VERSION "DIPBNNNYYYYYYYYYYYNNNNNNNNNNNNYNNNNNNNNNNN/4/%%%/4/'%**4NNN///"

BS_:

BU_:

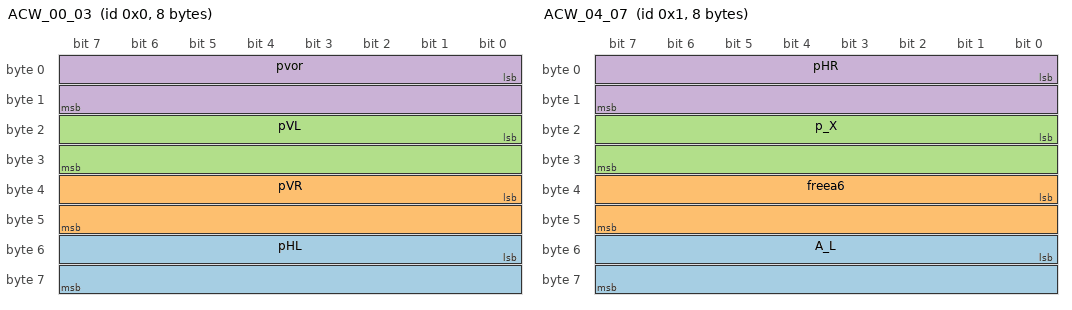
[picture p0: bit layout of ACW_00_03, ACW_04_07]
BO_ 0 ACW_00_03: 8 TX
 SG_ pHL : 48|16@1- (0.00813802,0) [0|250] "Bar" RX
 SG_ pVR : 32|16@1- (0.00813802,0) [0|250] "Bar" RX
 SG_ pVL : 16|16@1- (0.00813802,0) [0|250] "Bar" RX
 SG_ pvor : 0|16@1- (0.00813802,0) [0|250] "Bar" RX

BO_ 1 ACW_04_07: 8 TX
 SG_ A_L : 48|16@1- (0.000598756,0) [-15|15] "m/s²" RX
 SG_ freea6 : 32|16@1- (0.000305176,0) [0|250] "V" RX
 SG_ p_X : 16|16@1- (0.00813802,0) [0|250] "Bar" RX
 SG_ pHR : 0|16@1- (0.00813802,0) [0|250] "Bar" RX

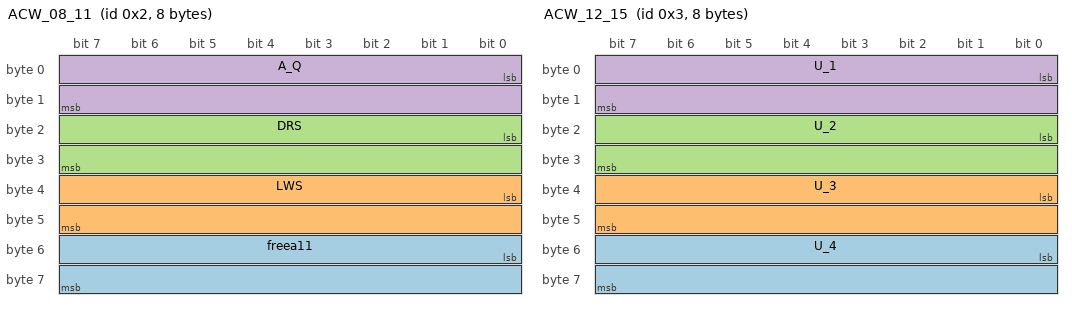
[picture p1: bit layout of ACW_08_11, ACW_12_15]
BO_ 2 ACW_08_11: 8 TX
 SG_ freea11 : 48|16@1- (0.000305176,0) [0|20] "V" RX
 SG_ LWS : 32|16@1- (0.000305176,0) [-180|180] "Grad" RX
 SG_ DRS : 16|16@1- (0.00338983,0) [-100|100] "°/s" RX
 SG_ A_Q : 0|16@1- (0.000598756,0) [-15|15] "m/s²" RX

BO_ 3 ACW_12_15: 8 TX
 SG_ U_4 : 48|16@1- (0.000305176,0) [0|20] "V" RX
 SG_ U_3 : 32|16@1- (0.000305176,0) [0|20] "V" RX
 SG_ U_2 : 16|16@1- (0.000305176,0) [0|20] "V" RX
 SG_ U_1 : 0|16@1- (0.000305176,0) [0|20] "V" RX

CM_ "  
!!!! do not edit - only for WinACW !!!!
[WINACWID] 1682 
[WINACWSIGNAL_T0] T_VL -50 950 °C 
[WINACWSIGNAL_T1] T_VR -50 950 °C 
[WINACWSIGNAL_T2] T_HL -50 950 °C 
[WINACWSIGNAL_T3] T_HR -50 950 °C 
[WINACWID] 1686 
[WINACWSIGNAL_T4] T_1_0 -50 950 °C 
[WINACWSIGNAL_T5] T_1_1 -50 950 °C 
[WINACWSIGNAL_T6] T_1_2 -50 950 °C 
[WINACWSIGNAL_T7] T_1_3 -50 950 °C 
[WINACWID] 1690 
[WINACWSIGNAL_T8] T_2_0 -50 950 °C 
[WINACWSIGNAL_T9] T_2_1 -50 950 °C 
[WINACWSIGNAL_T10] T_2_2 -50 950 °C 
[WINACWSIGNAL_T11] T_2_3 -50 950 °C 
[WINACWID] 1694 
[WINACWSIGNAL_T12] T_3_0 -50 950 °C 
[WINACWSIGNAL_T13] T_3_1 -50 950 °C 
[WINACWSIGNAL_T14] T_3_2 -50 950 °C 
[WINACWSIGNAL_T15] T_3_3 -50 950 °C 
[WINACWSIGNAL_S0] I0 0.0001530000 0.0000000000 -5 5 A 
[WINACWSIGNAL_S1] I1 0.0001530000 0.0000000000 -5 5 A 
[WINACWSIGNAL_S2] I2 0.0001530000 0.0000000000 -5 5 A 
[WINACWSIGNAL_S3] I3 0.0001530000 0.0000000000 -5 5 A 
[WINACWSIGNAL_S4] I4 0.0001530000 0.0000000000 -5 5 A 
[WINACWSIGNAL_S5] I5 0.0001530000 0.0000000000 -5 5 A 
[WINACWSIGNAL_S6] U0 0.0006100000 0.0000000000 -20 20 V 
[WINACWSIGNAL_S7] U1 0.0006100000 0.0000000000 -20 20 V 
[WINACWSIGNAL_S8] U2 0.0006100000 0.0000000000 -20 20 V 
[WINACWSIGNAL_S9] U3 0.0006100000 0.0000000000 -20 20 V 
[WINACWSIGNAL_S10] U4 0.0006100000 0.0000000000 -20 20 V 
[WINACWSIGNAL_S11] U5 0.0006100000 0.0000000000 -20 20 V 
[WINACWSIGNAL_D0] EVVL 
[WINACWSIGNAL_D1] AVVL 
[WINACWSIGNAL_D2] EVVR 
[WINACWSIGNAL_D3] AVVR 
[WINACWSIGNAL_D4] EVHL 
[WINACWSIGNAL_D5] AVHL 
[WINACWSIGNAL_D6] EVHR 
[WINACWSIGNAL_D7] AVHR 
[WINACWSIGNAL_D8] USV1 
[WINACWSIGNAL_D9] USV2 
[WINACWSIGNAL_D10] ASV1 
[WINACWSIGNAL_D11] ASV2 
[WINACWSIGNAL_D12] BA_LO 
[WINACWSIGNAL_D13] MRA 
[WINACWSIGNAL_D14] VLPR1 
[WINACWSIGNAL_D15] VLPR2 
[WINACWSIGNAL_D18] DATA 
[WINACWSIGNAL_D19] BA_HI 
[WINACWSIGNAL_D20] MT_SY 
[WINACWSIGNAL_D21] CLOCK 
[WINACWSIGNAL_R0] A_X 0.0200000000 -40.9600000000 -15 15 m/s² 
[WINACWSIGNAL_R1] A_Y 0.0200000000 -40.9600000000 -15 15 m/s² 
[WINACWSIGNAL_R2] YawRate_Z 0.0800000000 -163.8400000000 -100 100 °/s 
!!!! do not edit - only for WinACW !!!!
";
CM_ BO_ 0 "ACW_00_03";
CM_ SG_ 0 pHL "AK 03";
CM_ SG_ 0 pVR "AK 02";
CM_ SG_ 0 pVL "AK 01";
CM_ SG_ 0 pvor "AK 00";
CM_ BO_ 1 "ACW_04_07";
CM_ SG_ 1 A_L "AK 07";
CM_ SG_ 1 freea6 "AK 06";
CM_ SG_ 1 p_X "AK 05";
CM_ SG_ 1 pHR "AK 04";
CM_ BO_ 2 "ACW_08_11";
CM_ SG_ 2 freea11 "AK 11";
CM_ SG_ 2 LWS "AK 10";
CM_ SG_ 2 DRS "AK 09";
CM_ SG_ 2 A_Q "AK 08";
CM_ BO_ 3 "ACW_12_15";
CM_ SG_ 3 U_4 "AK 15";
CM_ SG_ 3 U_3 "AK 14";
CM_ SG_ 3 U_2 "AK 13";
CM_ SG_ 3 U_1 "AK 12";
